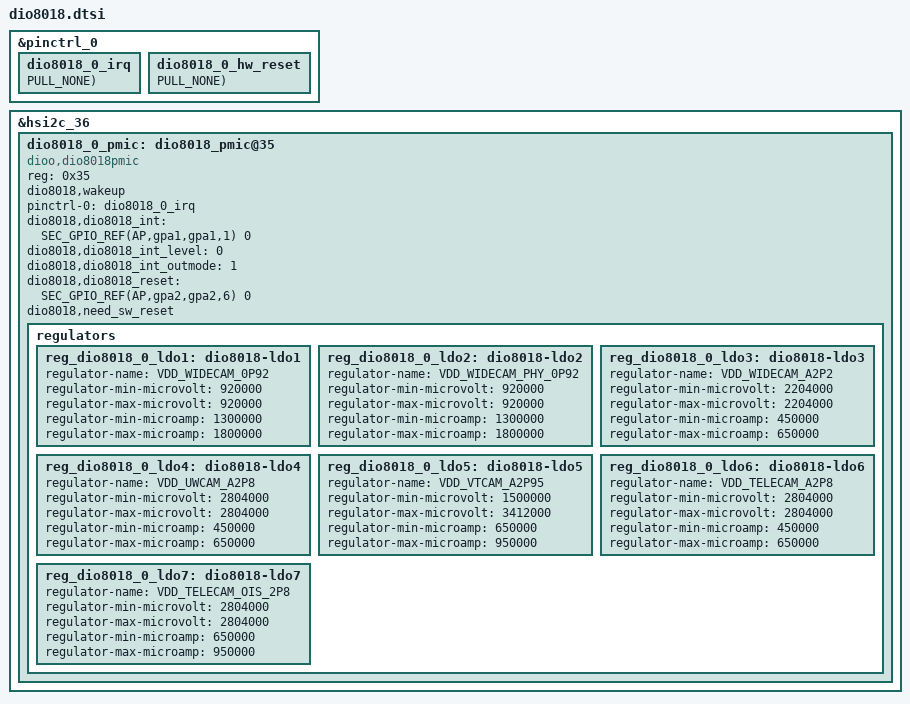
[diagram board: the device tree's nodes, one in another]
&pinctrl_0 {
	dio8018_0_irq: dio8018_0_irq {
		GPIO_CONFIG_PUD(AP,gpa1,gpa1,1, FUNC_INPUT, PULL_NONE);
	};
};

&pinctrl_0 {
	dio8018_0_hw_reset: dio8018_0_hw_reset {
		GPIO_CONFIG_PUD(AP,gpa2,gpa2,6, FUNC_OUTPUT_LOW, PULL_NONE);
	};
};

&hsi2c_36 {
	#address-cells = <1>;
	#size-cells = <0>;
	status = "okay";

	dio8018_0_pmic: dio8018_pmic@35{
		compatible = "dioo,dio8018pmic";
		reg = <0x35>;
		dio8018,wakeup;
		pinctrl-names = "default";
		pinctrl-0 = <&dio8018_0_irq>;
		dio8018,dio8018_int = <SEC_GPIO_REF(AP,gpa1,gpa1,1) 0>;
		dio8018,dio8018_int_level = <0>;
		dio8018,dio8018_int_outmode = <1>;
		dio8018,dio8018_reset = <SEC_GPIO_REF(AP,gpa2,gpa2,6) 0>;
		dio8018,need_sw_reset;

		regulators {
			reg_dio8018_0_ldo1: dio8018-ldo1 {
				regulator-name = "VDD_WIDECAM_0P92";
				regulator-min-microvolt = <920000>;
				regulator-max-microvolt = <920000>;
				
				regulator-min-microamp = <1300000>;regulator-max-microamp = <1800000>;
			};

			reg_dio8018_0_ldo2: dio8018-ldo2 {
				regulator-name = "VDD_WIDECAM_PHY_0P92";
				regulator-min-microvolt = <920000>;
				regulator-max-microvolt = <920000>;
				
				regulator-min-microamp = <1300000>;regulator-max-microamp = <1800000>;
			};
	
			reg_dio8018_0_ldo3: dio8018-ldo3 {
				regulator-name = "VDD_WIDECAM_A2P2";
				regulator-min-microvolt = <2204000>;
				regulator-max-microvolt = <2204000>;
				
				regulator-min-microamp = <450000>;regulator-max-microamp = <650000>;
			};

			reg_dio8018_0_ldo4: dio8018-ldo4 {
				regulator-name = "VDD_UWCAM_A2P8";
				regulator-min-microvolt = <2804000>;
				regulator-max-microvolt = <2804000>;
				
				regulator-min-microamp = <450000>;regulator-max-microamp = <650000>;
			};

			reg_dio8018_0_ldo5: dio8018-ldo5 {
				regulator-name = "VDD_VTCAM_A2P95";
				regulator-min-microvolt = <1500000>;
				regulator-max-microvolt = <3412000>;
				
				regulator-min-microamp = <650000>;regulator-max-microamp = <950000>;

			};

			reg_dio8018_0_ldo6: dio8018-ldo6 {
				regulator-name = "VDD_TELECAM_A2P8";
				regulator-min-microvolt = <2804000>;
				regulator-max-microvolt = <2804000>;
				
				regulator-min-microamp = <450000>;regulator-max-microamp = <650000>;
			};

			reg_dio8018_0_ldo7: dio8018-ldo7 {
				regulator-name = "VDD_TELECAM_OIS_2P8";
				regulator-min-microvolt = <2804000>;
				regulator-max-microvolt = <2804000>;
				
				regulator-min-microamp = <650000>;regulator-max-microamp = <950000>;
			};
		};
	};
};
